# KD32F328CB register map
File version: 1.0
Registers are 32-bit, read-write, reset 0x0 unless marked. A register's access mark holds for its fields unless they carry their own. Offsets are from the block's base; [hi:lo] are bit positions.

## COMP — Comparator
Base 0x4001001C
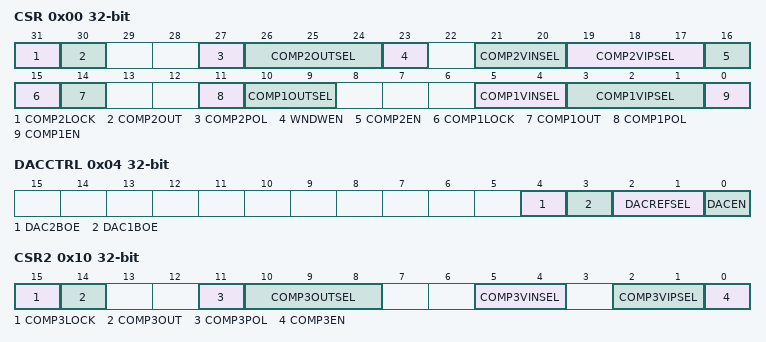
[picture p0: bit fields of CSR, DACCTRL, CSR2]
0x00 CSR access per field — control and status register
  [31] COMP2LOCK rw — Comparator 2 lock
  [30] COMP2OUT ro — Comparator 2 output
  [27] COMP2POL rw — Comparator 2 output polarity
  [26:24] COMP2OUTSEL rw — Comparator 2 output selection
  [23] WNDWEN rw — Window mode enable
  [21:20] COMP2VINSEL rw — Comparator 2 inverting input selection
  [19:17] COMP2VIPSEL rw — Comparator 2 mode
  [16] COMP2EN rw — Comparator 2 enable
  [15] COMP1LOCK rw — Comparator 1 lock
  [14] COMP1OUT rw — Comparator 1 hysteresis
  [11] COMP1POL rw — Comparator 1 output selection
  [10:9] COMP1OUTSEL rw — Comparator 1 inverting input selection
  [5:4] COMP1VINSEL rw — Comparator 1 mode
  [3:1] COMP1VIPSEL rw
  [0] COMP1EN rw — Comparator 1 enable
0x04 DACCTRL
  [4] DAC2BOE, [3] DAC1BOE, [2:1] DACREFSEL, [0] DACEN
0x08 DAC1DATA
  [6:0] DAC1DATA
0x0C DAC2DATA
  [6:0] DAC2DATA
0x10 CSR2 — control and status register
  [15] COMP3LOCK — Comparator 1 lock
  [14] COMP3OUT — Comparator 1 hysteresis
  [11] COMP3POL — Comparator 1 output selection
  [10:8] COMP3OUTSEL — Comparator 1 inverting input selection
  [5:4] COMP3VINSEL — Comparator 1 mode
  [2:1] COMP3VIPSEL — COMP1VIPSEL
  [0] COMP3EN — Comparator 1 enable

## TIM16 — General-purpose-timers
Base 0x40014400
Same registers: TIM17 0x40014800
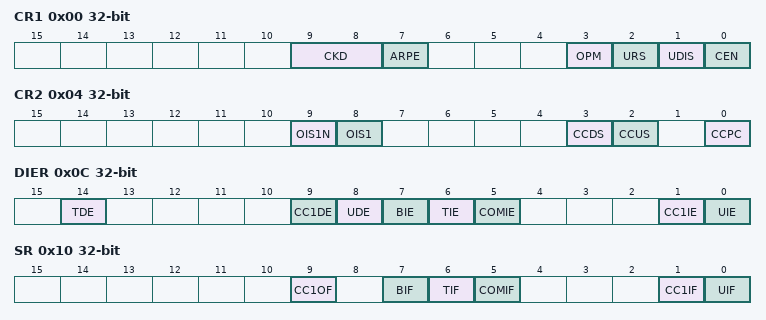
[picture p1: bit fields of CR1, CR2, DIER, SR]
0x00 CR1 — control register 1
  [9:8] CKD — Clock division
  [7] ARPE — Auto-reload preload enable
  [3] OPM — One-pulse mode
  [2] URS — Update request source
  [1] UDIS — Update disable
  [0] CEN — Counter enable
0x04 CR2 — control register 2
  [9] OIS1N — Output Idle state 1
  [8] OIS1 — Output Idle state 1
  [3] CCDS — Capture/compare DMA selection
  [2] CCUS — Capture/compare control update selection
  [0] CCPC — Capture/compare preloaded control
0x0C DIER — DMA/Interrupt enable register
  [14] TDE — Trigger DMA request enable
  [9] CC1DE — Capture/Compare 1 DMA request enable
  [8] UDE — Update DMA request enable
  [7] BIE — Break interrupt enable
  [6] TIE — Trigger interrupt enable
  [5] COMIE — COM interrupt enable
  [1] CC1IE — Capture/Compare 1 interrupt enable
  [0] UIE — Update interrupt enable
0x10 SR — status register
  [9] CC1OF — Capture/Compare 1 overcapture flag
  [7] BIF — Break interrupt flag
  [6] TIF — Trigger interrupt flag
  [5] COMIF — COM interrupt flag
  [1] CC1IF — Capture/compare 1 interrupt flag
  [0] UIF — Update interrupt flag
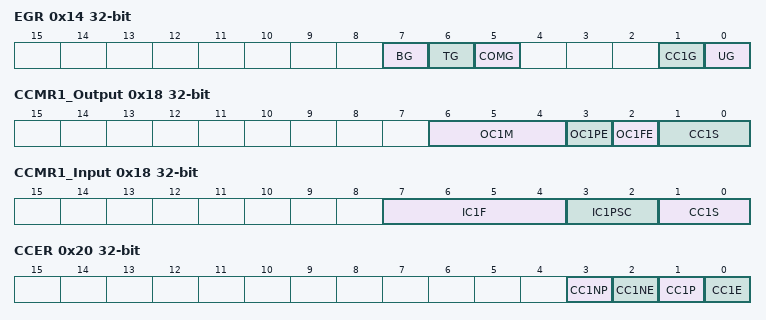
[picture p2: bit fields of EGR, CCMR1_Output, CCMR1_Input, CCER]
0x14 EGR wo — event generation register
  [7] BG — Break generation
  [6] TG — Trigger generation
  [5] COMG — Capture/Compare control update generation
  [1] CC1G — Capture/compare 1 generation
  [0] UG — Update generation
0x18 CCMR1_Output — capture/compare mode register (output mode)
  [6:4] OC1M — Output Compare 1 mode
  [3] OC1PE — Output Compare 1 preload enable
  [2] OC1FE — Output Compare 1 fast enable
  [1:0] CC1S — Capture/Compare 1 selection
0x18 CCMR1_Input (alternate view of CCMR1_Output) — capture/compare mode register 1 (input mode)
  [7:4] IC1F — Input capture 1 filter
  [3:2] IC1PSC — Input capture 1 prescaler
  [1:0] CC1S — Capture/Compare 1 selection
0x20 CCER — capture/compare enable register
  [3] CC1NP — Capture/Compare 1 output Polarity
  [2] CC1NE — Capture/Compare 1 complementary output enable
  [1] CC1P — Capture/Compare 1 output Polarity
  [0] CC1E — Capture/Compare 1 output enable
0x24 CNT — counter
  [15:0] CNT — counter value
0x28 PSC — prescaler
  [15:0] PSC — Prescaler value
0x2C ARR — auto-reload register
  [15:0] ARR — Auto-reload value
0x30 RCR — repetition counter register
  [7:0] REP — Repetition counter value
0x34 CCR1 — capture/compare register 1
  [15:0] CCR1 — Capture/Compare 1 value
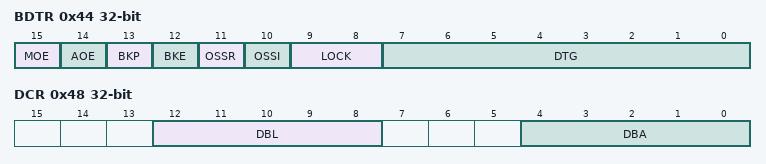
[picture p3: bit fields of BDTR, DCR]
0x44 BDTR — break and dead-time register
  [15] MOE — Main output enable
  [14] AOE — Automatic output enable
  [13] BKP — Break polarity
  [12] BKE — Break enable
  [11] OSSR — Off-state selection for Run mode
  [10] OSSI — Off-state selection for Idle mode
  [9:8] LOCK — Lock configuration
  [7:0] DTG — Dead-time generator setup
0x48 DCR — DMA control register
  [12:8] DBL — DMA burst length
  [4:0] DBA — DMA base address
0x4C DMAR — DMA address for full transfer
  [15:0] DMAB — DMA register for burst accesses
